# apollo3 register map
Vendor: Ambiq Micro; Series: Apollo; File version: 1.0
CPU: CM4 r1p0, little endian, MPU, FPU, 3 interrupt priority bits
Registers are 32-bit, read-write, reset 0x0 unless marked. A register's access mark holds for its fields unless they carry their own. Offsets are from the block's base; [hi:lo] are bit positions; 'fields as' and 'values as' point back to an identical list.

## BLEIF — BLE Interface
Base 0x5000C000
0x00 FIFO — FIFO Access Port
  [31:0] FIFO — FIFO direct access. Only locations 0 - 3F will return valid information.
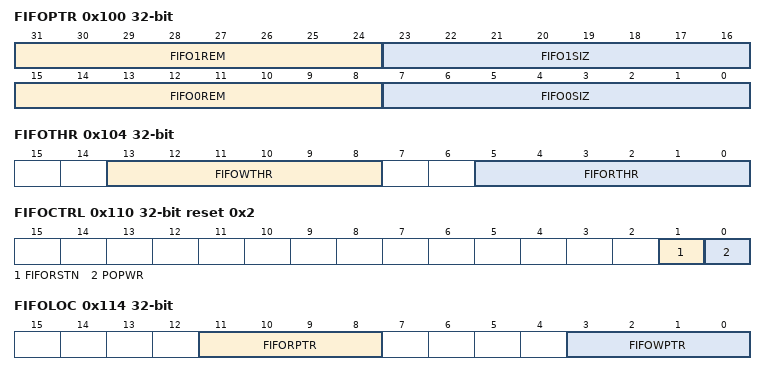
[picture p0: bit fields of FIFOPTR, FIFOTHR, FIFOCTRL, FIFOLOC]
0x100 FIFOPTR — FIFO size and remaining slots open values
  [31:24] FIFO1REM — The number of remaining data bytes slots currently in FIFO 1 (written by interface, read by MCU)
  [23:16] FIFO1SIZ — The number of valid data bytes currently in FIFO 1 (written by interface, read by MCU)
  [15:8] FIFO0REM — The number of remaining data bytes slots currently in FIFO 0 (written by MCU, read by interface)
  [7:0] FIFO0SIZ — The number of valid data bytes currently in the FIFO 0 (written by MCU, read by interface)
0x104 FIFOTHR — FIFO Threshold Configuration
  [13:8] FIFOWTHR — FIFO write threshold in bytes. A value of 0 will disable the write FIFO level from activating the threshold interrupt. If this field is non-zero, it will trigger a threshold interrupt when the write fifo contains FIFOWTHR free bytes, as indicated by the FIFO0REM field. This is intended to signal when a transfer of FIFOWTHR bytes can be done from the host to the IOM write fifo to support large IOM write operations.
  [5:0] FIFORTHR — FIFO read threshold in bytes. A value of 0 will disable the read FIFO level from activating the threshold interrupt. If this field is non-zero, it will trigger a threshold interrupt when the read fifo contains FIFORTHR valid bytes of data, as indicated by the FIFO1SIZ field. This is intended to signal when a data transfer of FIFORTHR bytes can be done from the IOM module to the host via the read fifo to support large IOM read operations.
0x108 FIFOPOP
  [31:0] FIFODOUT — This register will return the read data indicated by the current read pointer on reads. If the POPWR control bit in the FIFOCTRL register is reset (0), the fifo read pointer will be advanced by one word as a result of the read. If the POPWR bit is set (1), the fifo read pointer will only be advanced after a write operation to this register. The write data is ignored for this register. If less than a even word multiple is available, and the command is completed, the module will return the word containing these bytes and undetermined data in the unused fields of the word.
0x10C FIFOPUSH
  [31:0] FIFODIN — This register is used to write the FIFORAM in FIFO mode and will cause a push event to occur to the next open slot within the FIFORAM. Writing to this register will cause the write point to increment by 1 word(4 bytes).
0x110 FIFOCTRL reset 0x2 — FIFO Control Register
  [1] FIFORSTN — Active low manual reset of the fifo. Write to 0 to reset fifo, and then write to 1 to remove the reset.
  [0] POPWR — Selects the mode in which 'pop' events are done for the fifo read operations. A value of '1' will prevent a pop event on a read operation, and will require a write to the FIFOPOP register to create a pop event. A value of '0' in this register will allow a pop event to occur on the read of the FIFOPOP register, and may cause inadvertant fifo pops when used in a debugging mode.
0x114 FIFOLOC — FIFO Pointers
  [11:8] FIFORPTR — Current FIFO read pointer. Used to index into the incoming FIFO (FIFO1), which is used to store read data returned from external devices during a read operation.
  [3:0] FIFOWPTR — Current FIFO write pointer. Value is the index into the outgoing FIFO (FIFO0), which is used during write operations to external devices.
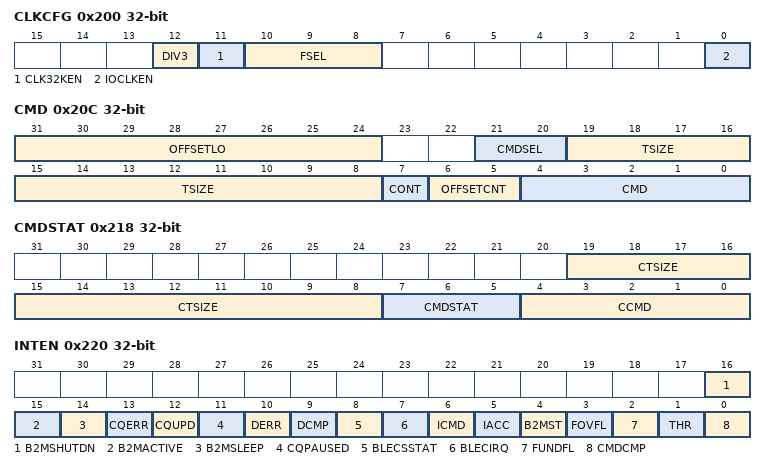
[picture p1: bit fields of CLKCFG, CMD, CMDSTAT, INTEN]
0x200 CLKCFG — I/O Clock Configuration
  [12] DIV3 — Enable of the divide by 3 of the source IOCLK.
  [11] CLK32KEN — Enable for the 32Khz clock to the BLE module
  [10:8] FSEL — Select the input clock frequency.
    0=MIN_PWR (Selects the minimum power clock. This setting should be used whenever the IOM is not active. value.); 1=HFRC (Selects the HFRC as the input clock. value.); 2=HFRC_DIV2 (Selects the HFRC / 2 as the input clock. value.); 3=HFRC_DIV4 (Selects the HFRC / 4 as the input clock. value.); 4=HFRC_DIV8 (Selects the HFRC / 8 as the input clock. value.); 5=HFRC_DIV16 (Selects the HFRC / 16 as the input clock. value.); 6=HFRC_DIV32 (Selects the HFRC / 32 as the input clock. value.); 7=HFRC_DIV64 (Selects the HFRC / 64 as the input clock. value.)
  [0] IOCLKEN — Enable for the interface clock. Must be enabled prior to executing any IO operations.
0x20C CMD — Command and offset Register
  [31:24] OFFSETLO — This register holds the low order byte of offset to be used in the transaction. The number of offset bytes to use is set with bits 1:0 of the command. Offset bytes are transferred starting from the highest byte first.
  [21:20] CMDSEL — Command Specific selection information
  [19:8] TSIZE — Defines the transaction size in bytes. The offset transfer is not included in this size.
  [7] CONT — Contine to hold the bus after the current transaction if set to a 1 with a new command issued.
  [6:5] OFFSETCNT — Number of offset bytes to use for the command - 0, 1, 2, 3 are valid selections. The second (byte 1) and third byte (byte 2) are read from the OFFSETHI register, and the low order byte is pulled from this register in the OFFSETLO field. Offset bytes are transmitted highest byte first. EG if offsetcnt == 3, OFFSETHI[15:8] will be transmitted first, then OFFSETHI[7:0] then OFFSETLO. If offsetcnt == 2, OFFSETHI[7:0] will be transmitted, then OFFSETLO. If offsetcnt == 1, only OFFSETLO will be transmitted. Offset bytes are always transmitted MSB first, regardless of the value of the LSB control bit within the module configuration.
  [4:0] CMD — Command for submodule.
    1=WRITE (Write command using count of offset bytes specified in the OFFSETCNT field value.); 2=READ (Read command using count of offset bytes specified in the OFFSETCNT field value.)
0x210 CMDRPT — Command Repeat Register
  [4:0] CMDRPT — Count of number of times to repeat the next command.
0x214 OFFSETHI — High order offset bytes
  [15:0] OFFSETHI — Holds the high order bytes of the 2 or 3 byte offset phase of a transaction.
0x218 CMDSTAT — Command status
  [19:8] CTSIZE — The current number of bytes still to be transferred with this command. This field will count down to zero.
  [7:5] CMDSTAT — The current status of the command execution.
    1=ERR (Error encountered with command value.); 2=ACTIVE (Actively processing command value.); 4=IDLE (Idle state, no active command, no error value.); 6=WAIT (Command in progress, but waiting on data from host value.)
  [4:0] CCMD — current command that is being executed
0x220 INTEN — IO Master Interrupts: Enable
  [16] B2MSHUTDN — The B2M_STATE from the BLE Core transitioned into shutdown state
  [15] B2MACTIVE — The B2M_STATE from the BLE Core transitioned into the active state
  [14] B2MSLEEP — The B2M_STATE from the BLE Core transitioned into the sleep state
  [13] CQERR — Command queue error during processing. When an error occurs, the system will stop processing and halt operations to allow software to take recovery actions
  [12] CQUPD — Command queue write operation executed a register write with the register address bit 0 set to 1. The low address bits in the CQ address fields are unused and bit 0 can be used to trigger an interrupt to indicate when this register write is performed by the CQ operation.
  [11] CQPAUSED — Command queue is paused due to an active event enabled in the PAUSEEN register. The interrupt is posted when the event is enabled within the PAUSEEN register, the mask is active in the CQIRQMASK field and the event occurs.
  [10] DERR — DMA Error encountered during the processing of the DMA command. The DMA error could occur when the memory access specified in the DMA operation is not available or incorrectly specified.
  [9] DCMP — DMA Complete. Processing of the DMA operation has completed and the DMA submodule is returned into the idle state
  [8] BLECSSTAT — BLE Core SPI Status interrupt. Asserted when the SPI_STATUS signal from the BLE Core is asserted, indicating that SPI writes can be done to the BLE Core. Transfers to the BLE Core should only be done when this signal is high.
  [7] BLECIRQ — BLE Core IRQ signal. Asserted when the BLE_IRQ signal from the BLE Core is asserted, indicating the availability of read data from the BLE Core.
  [6] ICMD — illegal command interrupt. Asserted when a command is written when an active command is in progress.
  [5] IACC — illegal FIFO access interrupt. Asserted when there is a overflow or underflow event
  [4] B2MST — B2M State change interrupt. Asserted on any change in the B2M_STATE signal from the BLE Core.
  [3] FOVFL — Write FIFO Overflow interrupt. This occurs when software tries to write to a full fifo. The current operation does not stop.
  [2] FUNDFL — Read FIFO Underflow interrupt. Asserted when a pop operation is done to a empty read FIFO.
  [1] THR — FIFO Threshold interrupt. For write operations, asserted when the number of free bytes in the write FIFO equals or exceeds the WTHR field. For read operations, asserted when the number of valid bytes in the read FIFO equals of exceeds the value set in the RTHR field.
  [0] CMDCMP — Command Complete interrupt. Asserted when the current operation has completed. For repeated commands, this will only be asserted when the final repeated command is completed.
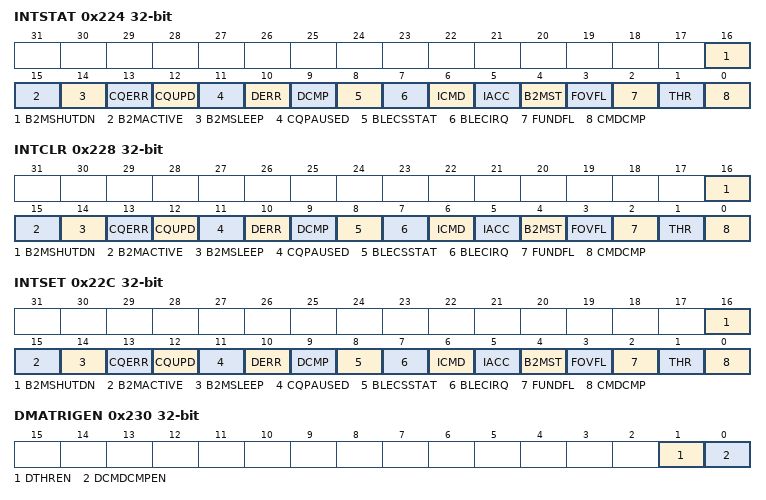
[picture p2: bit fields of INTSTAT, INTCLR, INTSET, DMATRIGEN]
0x224 INTSTAT — IO Master Interrupts: Status
  fields as INTEN
0x228 INTCLR — IO Master Interrupts: Clear
  fields as INTEN
0x22C INTSET — IO Master Interrupts: Set
  fields as INTEN
0x230 DMATRIGEN — DMA Trigger Enable Register
  [1] DTHREN — Trigger DMA upon THR level reached. For M2P DMA operations (IOM writes), the trigger will assert when the write FIFO has (WTHR/4) number of words free in the write FIFO, and will transfer (WTHR/4) number of words or, if the number of words left to transfer is less than the WTHR value, will transfer the remaining byte count. For P2M DMA operations, the trigger will assert when the read FIFO has (RTHR/4) words available in the read FIFO, and will transfer (RTHR/4) words to SRAM. This trigger will NOT assert when the transaction completes and there are less than RTHR bytes left in the fifo, since the RTHR has not been reached. In this case, enabling the CMDCMP trigger will transfer the remaining data from the commmand. If the CMDCMP trigger is not enabled, the module will initiate a transfer when the amount of data in the FIFO is equal to or greater than the remaining data in the DMA. In cases where one DMA setup covers multiple commands, this will only occur at the end of the last transaction when the DMA is near complete.
  [0] DCMDCMPEN — Trigger DMA upon command complete. Enables the trigger of the DMA when a command is completed. When this event is triggered, the number of words transferred will be the lesser of the remaining TOTCOUNT bytes, or the number of bytes in the FIFO when the command completed. If this is disabled, and the number of bytes in the FIFO is equal or greater than the TOTCOUNT bytes, a transfer of TOTCOUNT bytes will be done to ensure read data is stored when the DMA is completed.
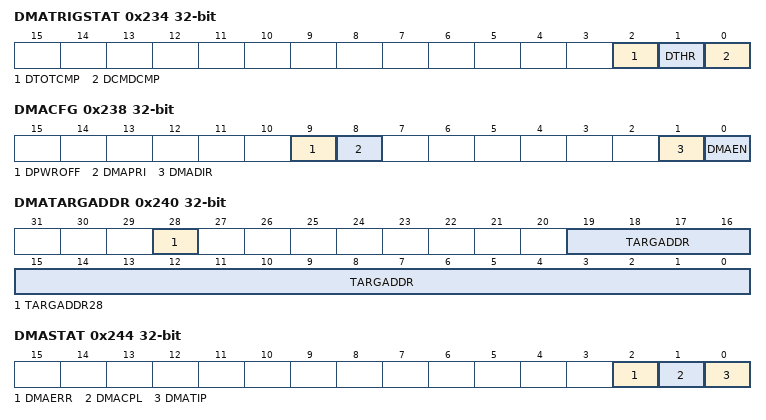
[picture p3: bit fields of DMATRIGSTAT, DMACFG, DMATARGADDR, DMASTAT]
0x234 DMATRIGSTAT — DMA Trigger Status Register
  [2] DTOTCMP — DMA triggered when DCMDCMP = 0, and the amount of data in the FIFO was enough to complete the DMA operation (greater than or equal to current TOTCOUNT) when the command completed. This trigger is default active when the DCMDCMP trigger is disabled and there is enough data in the FIFO to complete the DMA operation.
  [1] DTHR — Triggered DMA from THR event. Bit is read only and can be cleared by disabling the DTHR trigger enable or by disabling DMA.
  [0] DCMDCMP — Triggered DMA from Command complete event. Bit is read only and can be cleared by disabling the DCMDCMP trigger enable or by disabling DMA.
0x238 DMACFG — DMA Configuration Register
  [9] DPWROFF — Power off module after DMA is complete. If this bit is active, the module will request to power off the supply it is attached to. If there are other units still requiring power from the same domain, power down will not be performed.
    0=DIS (Power off disabled value.); 1=EN (Power off enabled value.)
  [8] DMAPRI — Sets the Priority of the DMA request
    0=LOW (Low Priority (service as best effort) value.); 1=HIGH (High Priority (service immediately) value.)
  [1] DMADIR — Direction
    0=P2M (Peripheral to Memory (SRAM) transaction. To be set when doing IOM read operations, ie reading data from external devices. value.); 1=M2P (Memory to Peripheral transaction. To be set when doing IOM write operations, ie writing data to external devices. value.)
  [0] DMAEN — DMA Enable. Setting this bit to EN will start the DMA operation. This should be the last DMA related register set prior to issuing the command
    0=DIS (Disable DMA Function value.); 1=EN (Enable DMA Function value.)
0x23C DMATOTCOUNT — DMA Total Transfer Count
  [11:0] TOTCOUNT — Triggered DMA from Command complete event occured. Bit is read only and can be cleared by disabling the DTHR trigger enable or by disabling DMA.
0x240 DMATARGADDR — DMA Target Address Register
  [28] TARGADDR28 — Bit 28 of the target byte address for source of DMA (either read or write). In cases of non-word aligned addresses, the DMA logic will take care for ensuring only the target bytes are read/written. Setting to '1' will select the SRAM. Setting to '0' will select the flash
  [19:0] TARGADDR — Bits [19:0] of the target byte address for source of DMA (either read or write). The address can be any byte alignment, and does not have to be word aligned. In cases of non-word aligned addresses, the DMA logic will take care for ensuring only the target bytes are read/written.
0x244 DMASTAT — DMA Status Register
  [2] DMAERR — DMA Error. This active high bit signals that an error was encountered during the DMA operation.
  [1] DMACPL — DMA Transfer Complete. This signals the end of the DMA operation. This bit can be cleared by writing to 0.
  [0] DMATIP — DMA Transfer In Progress indicator. 1 will indicate that a DMA transfer is active. The DMA transfer may be waiting on data, transferring data, or waiting for priority. All of these will be indicated with a 1. A 0 will indicate that the DMA is fully complete and no further transactions will be done. This bit is read only.
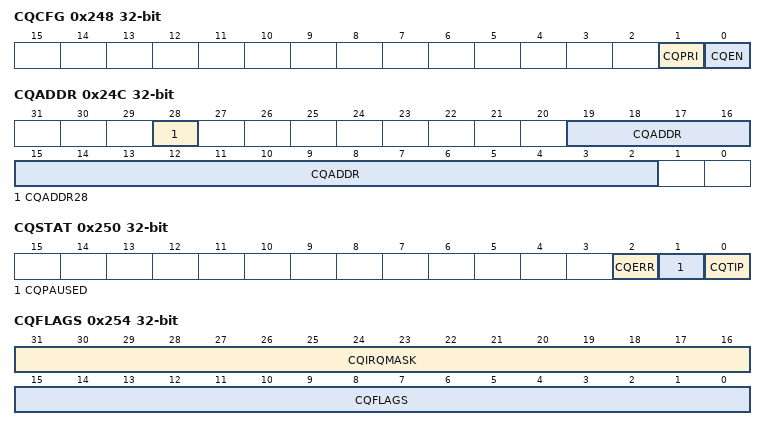
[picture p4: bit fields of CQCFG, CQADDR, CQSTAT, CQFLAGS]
0x248 CQCFG — Command Queue Configuration Register
  [1] CQPRI — Sets the Priority of the command queue dma request.
    values as DMACFG.DMAPRI
  [0] CQEN — Command queue enable. When set, will enable the processing of the command queue and fetches of address/data pairs will proceed from the word address within the CQADDR register. Can be disabled using a CQ executed write to this bit as well.
    0=DIS (Disable CQ Function value.); 1=EN (Enable CQ Function value.)
0x24C CQADDR — CQ Target Read Address Register
  [28] CQADDR28 — Bit 28 of target byte address for source of CQ (read only). Used to denote Flash (0) or SRAM (1) access
  [19:2] CQADDR — Bits 19:2 of target byte address for source of CQ (read only). The buffer must be aligned on a word boundary
0x250 CQSTAT — Command Queue Status Register
  [2] CQERR — Command queue processing Error. This active high bit signals that an error was encountered during the CQ operation.
  [1] CQPAUSED — Command queue operation is currently paused.
  [0] CQTIP — Command queue Transfer In Progress indicator. 1 will indicate that a CQ transfer is active and this will remain active even when paused waiting for external event.
0x254 CQFLAGS — Command Queue Flag Register
  [31:16] CQIRQMASK — Provides for a per-bit mask of the flags used to invoke an interrupt. A '1' in the bit position will enable the pause event to trigger the interrupt, if the CQWT_int interrupt is enabled. Bits definitions are the same as CQPAUSE
  [15:0] CQFLAGS — Current flag status (read-only). Bits [7:0] are software controllable and bits [15:8] are hardware status.
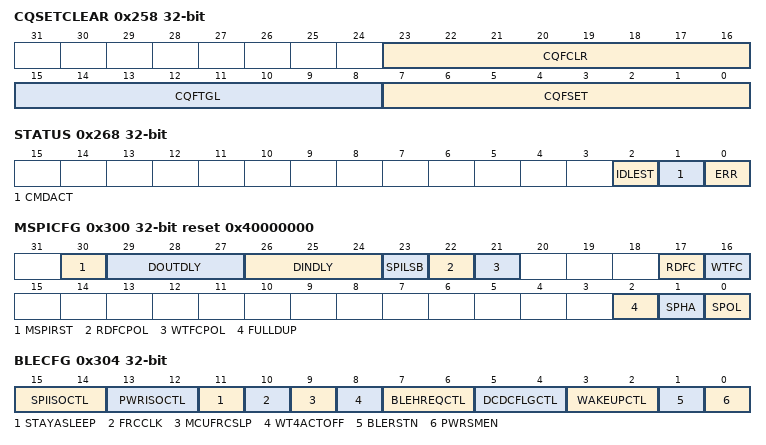
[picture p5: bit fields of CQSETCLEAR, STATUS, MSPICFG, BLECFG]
0x258 CQSETCLEAR — Command Queue Flag Set/Clear Register
  [23:16] CQFCLR — Clear CQFlag status bits. Will clear to 0 any SWFLAG with a '1' in the corresponding bit position of this field
  [15:8] CQFTGL — Toggle the indicated bit. Will toggle the value of any SWFLAG with a '1' in the corresponding bit position of this field
  [7:0] CQFSET — Set CQFlag status bits. Will set to 1 the value of any SWFLAG with a '1' in the corresponding bit position of this field
0x25C CQPAUSEEN — Command Queue Pause Enable Register
  [15:0] CQPEN — Enables the specified event to pause command processing when active
    0x8000=CNTEQ (Pauses command queue processing when HWCNT matches SWCNT value.); 0x4000=BLEXOREN (Pause command queue when input BLE bit XORed with SWFLAG4 is '1' value.); 0x2000=IOMXOREN (Pause command queue when input IOM bit XORed with SWFLAG3 is '1' value.); 0x1000=GPIOXOREN (Pause command queue when input GPIO irq_bit XORed with SWFLAG2 is '1' value.); 0x800=MSPI1XNOREN (Pause command queue when input MSPI1 bit XNORed with SWFLAG1 is '1' value.); 0x400=MSPI0XNOREN (Pause command queue when input MSPI0 bit XNORed with SWFLAG0 is '1' value.); 0x200=MSPI1XOREN (Pause command queue when input MSPI1 bit XORed with SWFLAG1 is '1' value.); 0x100=MSPI0XOREN (Pause command queue when input MSPI0 bit XORed with SWFLAG0 is '1' value.); 128=SWFLAGEN7 (Pause the command queue when software flag bit 7 is '1'. value.); 64=SWFLAGEN6 (Pause the command queue when software flag bit 7 is '1' value.); 32=SWFLAGEN5 (Pause the command queue when software flag bit 7 is '1' value.); 16=SWFLAGEN4 (Pause the command queue when software flag bit 7 is '1' value.); 8=SWFLAGEN3 (Pause the command queue when software flag bit 7 is '1' value.); 4=SWFLAGEN2 (Pause the command queue when software flag bit 7 is '1' value.); 2=SWFLAGEN1 (Pause the command queue when software flag bit 7 is '1' value.); 1=SWFLGEN0 (Pause the command queue when software flag bit 7 is '1' value.)
0x260 CQCURIDX — IOM Command Queue current index value . Compared to the CQENDIDX reg contents to generate the IDXEQ Pause event for command queue
  [7:0] CQCURIDX — Holds 8 bits of data that will be compared with the CQENDIX register field. If the values match, the IDXEQ pause event will be activated, which will cause the pausing of command quue operation if the IDXEQ bit is enabled in CQPAUSEEN.
0x264 CQENDIDX — IOM Command Queue current index value . Compared to the CQCURIDX reg contents to generate the IDXEQ Pause event for command queue
  [7:0] CQENDIDX — Holds 8 bits of data that will be compared with the CQCURIX register field. If the values match, the IDXEQ pause event will be activated, which will cause the pausing of command quue operation if the IDXEQ bit is enabled in CQPAUSEEN.
0x268 STATUS — IOM Module Status Register
  [2] IDLEST — indicates if the active I/O state machine is IDLE. Note - The state machine could be in idle state due to holdoffs from data availability, or as the command gets propagated into the logic from the registers.
    1=IDLE (The I/O state machine is in the idle state. value.)
  [1] CMDACT — Indicates if the active I/O Command is currently processing a transaction, or command is complete, but the FIFO pointers are still syncronizing internally. This bit will go high at the start of the transaction, and will go low when the command is complete, and the data and pointers within the FIFO have been syncronized.
    1=ACTIVE (An I/O command is active. Indicates the active module has an active command and is processing this. De-asserted when the command is completed. value.)
  [0] ERR — Bit has been deprecated. Please refer to the other error indicators. This will always return 0.
    1=ERROR (Bit has been deprecated and will always return 0. value.)
0x300 MSPICFG reset 0x40000000 — SPI module master configuration
  [30] MSPIRST — Bit is deprecated. setting it will have no effect.
  [29:27] DOUTDLY — Delay tap to use for the output signal (MOSI). This give more hold time on the output data.
  [26:24] DINDLY — Delay tap to use for the input signal (MISO). This gives more hold time on the input data.
  [23] SPILSB — Selects data transfer as MSB first (0) or LSB first (1) for the data portion of the SPI transaction. The offset bytes are always transmitted MSB first.
    0=MSB (Send and receive MSB bit first value.); 1=LSB (Send and receive LSB bit first value.)
  [22] RDFCPOL — Selects the read flow control signal polarity. When set, the clock will be held low until the flow control is de-asserted.
    0=NORMAL (SPI_STATUS signal from BLE Core high(1) creates flow control and new read spi transactions will not be started until the signal goes low.(default) value.); 1=INVERTED (SPI_STATUS signal from BLE Core low(0) creates flow control and new read spi transactions will not be started until the signal goes high. value.)
  [21] WTFCPOL — Selects the write flow control signal polarity. The transfers are halted when the selected flow control signal is OPPOSITE polarity of this bit. (For example: WTFCPOL = 0 will allow a SPI_STATUS=1 to pause transfers).
    0=NORMAL (SPI_STATUS signal from BLE Core high(1) creates flow control and new write spi transactions will not be started until the signal goes low.(default) value.); 1=INVERTED (SPI_STATUS signal from BLE Core high(1) creates low(0) control and new write spi transactions will not be started until the signal goes high. value.)
  [17] RDFC — Enables flow control of new read transactions based on the SPI_STATUS signal from the BLE Core.
    0=DIS (Read mode flow control disabled. value.); 1=EN (Read mode flow control enabled. value.)
  [16] WTFC — Enables flow control of new write transactions based on the SPI_STATUS signal from the BLE Core.
    0=DIS (Write mode flow control disabled. value.); 1=EN (Write mode flow control enabled. value.)
  [2] FULLDUP — Full Duplex mode. Capture read data during writes operations
  [1] SPHA — Selects the SPI phase; When 1, will shift the sampling edge by 1/2 clock.
    0=SAMPLE_LEADING_EDGE (Sample on the leading (first) clock edge, rising or falling dependant on the value of SPOL value.); 1=SAMPLE_TRAILING_EDGE (Sample on the trailing (second) clock edge, rising of falling dependant on the value of SPOL value.)
  [0] SPOL — This bit selects SPI polarity.
    0=CLK_BASE_0 (The initial value of the clock is 0. value.); 1=CLK_BASE_1 (The initial value of the clock is 1. value.)
0x304 BLECFG — BLE Core Control
  [15:14] SPIISOCTL — Configuration of BLEH isolation controls for SPI related signals.
    3=ON (SPI signals from BLE Core to/from MCU Core are isolated. value.); 2=OFF (SPI signals from BLE Core to/from MCU Core are not isolated. value.); 0=AUTO (SPI signals from BLE Core to/from MCU Core are automatically isolated by the logic value.)
  [13:12] PWRISOCTL — Configuration of BLEH isolation control for power related signals.
    3=ON (BLEH power signal isolation to on (isolated). value.); 2=OFF (BLEH power signal isolation to off (not isolated). value.); 0=AUTO (BLEH Power signal isolation is controlled automatically through the interface logic value.)
  [11] STAYASLEEP — Set to prevent the BLE power control module from waking up the BLE Core after going into power down. To be used for graceful shutdown, set by software prior to powering off and will allow assertion of reset from sleep state.
  [10] FRCCLK — Force the clock in the BLEIF to be always running
  [9] MCUFRCSLP — Force power state machine to go to the sleep state. Intended for debug only. Has no effect on the actual BLE Core state, only the state of the BLEIF interface state machine.
  [8] WT4ACTOFF — Debug control of BLEIF power state machine. Allows transition into the active state in the BLEIF state without waiting for dcdc req from BLE Core.
  [7:6] BLEHREQCTL — BLEH power on request override. The value of this field will be sent to the BLE Core when the PWRSM is off. Otherwise, the value is supplied from internal logic.
    3=ON (BLEH Power-on reg signal is set to on (1). value.); 2=OFF (BLEH Power-on signal is set to off (0). value.); 0=AUTO (BLEH Power-on signal is controlled by the PWRSM logic and automatically controlled value.)
  [5:4] DCDCFLGCTL — DCDCFLG signal override. The value of this field will be sent to the BLE Core when the PWRSM is off. Otherwise, the value is supplied from internal logic.
    3=ON (DCDC Flag signal is set to on (1). value.); 2=OFF (DCDC Flag signal is set to off (0). value.); 0=AUTO (DCDC Flag signal is controlled by the PWRSM logic and automatically controlled value.)
  [3:2] WAKEUPCTL — WAKE signal override. Controls the source of the WAKE signal to the BLE Core.
    3=ON (Wake signal is set to on (1). value.); 2=OFF (Wake signal is set to off (0). value.); 0=AUTO (Wake signal is controlled by the PWRSM logic and automatically controlled value.)
  [1] BLERSTN — Reset line to the BLE Core. This will reset the BLE core when asserted ('0') and must be written to '1' prior to performing any BTLE related operations to the core.
    1=ACTIVE (The reset signal is active (0) value.); 0=INACTIVE (The reset signal is inactive (1) value.)
  [0] PWRSMEN — Enable the power state machine for automatic sequencing and control of power states of the BLE Core module.
    1=ON (Internal power state machine is enabled and will sequence the BLEH power domain as indicated in the design document. Overrides for the power signals are not enabled. value.); 0=OFF (Internal power state machine is disabled and will not sequence the BLEH power domain. The values of the overrides will be used to drive the output sequencing signals value.)
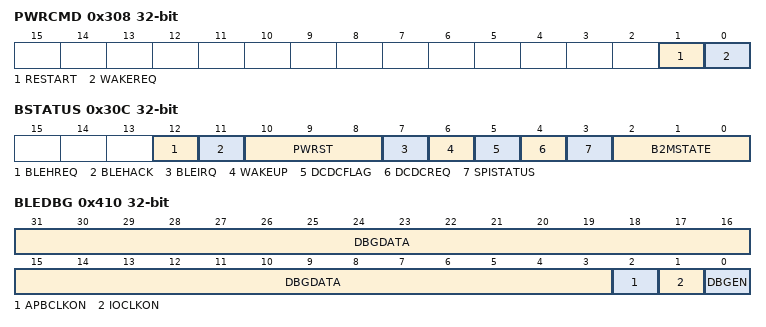
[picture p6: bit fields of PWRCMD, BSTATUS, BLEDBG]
0x308 PWRCMD — BLE Power command interface
  [1] RESTART — Restart the BLE Core after going into the shutdown state. Only valid when in the shutdown state.
  [0] WAKEREQ — Wake request from the MCU. When asserted (1), the BLE Interface logic will assert the wakeup request signal to the BLE Core. Only recognized when in the sleep state
0x30C BSTATUS — BLE Core status
  [12] BLEHREQ — Value of the BLEHREQ signal to the power control unit. The BLEHREQ signal is sent from the BLEIF module to the power control module to request the BLEH power up. When the BLEHACK signal is asserted, BLEH power is stable and ready for use.
  [11] BLEHACK — Value of the BLEHACK signal from the power control unit. If the signal is '1', the BLEH power is active and ready for use.
  [10:8] PWRST — Current status of the power state machine
    0=OFF (Internal power state machine is disabled and will not sequence the BLEH power domain. The values of the overrides will be used to drive the output sequencing signals value.); 1=INIT (Initialization state. BLEH not powered value.); 2=PWRON (Waiting for the powerup of the BLEH value.); 3=ACTIVE (The BLE Core is powered and active value.); 6=SLEEP (The BLE Core has entered sleep mode and the power request is inactive value.); 4=SHUTDOWN (The BLE Core is in shutdown mode value.)
  [7] BLEIRQ — Status of the BLEIRQ signal from the BLE Core. A value of 1 idicates that read data is available in the core and a read operation needs to be performed.
  [6] WAKEUP — Value of the WAKEUP signal to the BLE Core . The WAKEUP signals is sent from the BLEIF to the BLECORE to request the BLE Core transition from sleep state to active state.
  [5] DCDCFLAG — Value of the DCDCFLAG signal to the BLE Core. The DCDCFLAG is a signal to the BLE Core indicating that the BLEH ppower is active.
  [4] DCDCREQ — Value of the DCDCREQ signal from the BLE Core. The DCDCREQ signal is sent from the core to the BLEIF module when the BLE core requires BLEH power to be active. When activated, this is indicated by DCDCFLAG going to 1.
  [3] SPISTATUS — Value of the SPISTATUS signal from the BLE Core. The signal is asserted when the BLE Core is able to accept write data via the SPI interface. Data should be transmitted to the BLE core only when this signal is 1. The hardware will automatically wait for this signal prior to performing a write operation if flow control is active.
  [2:0] B2MSTATE — State of the BLE Core logic.
    0=RESET (Reset State value.); 1=Sleep state. value.; 2=Standby State value; 3=Idle state value; 4=Active state. value.
0x410 BLEDBG — BLEIF Master Debug Register
  [31:3] DBGDATA — Debug data
  [2] APBCLKON — APBCLK debug clock control. Enable APB_CLK to be active when this bit is '1'. Otherwise, the clock is controlled with gating from the logic as needed.
  [1] IOCLKON — IOCLK debug clock control. Enable IO_CLK to be active when this bit is '1'. Otherwise, the clock is controlled with gating from the logic as needed.
  [0] DBGEN — Debug Enable. Setting this bit will enable the update of data within this register, otherwise it is clock gated for power savings
